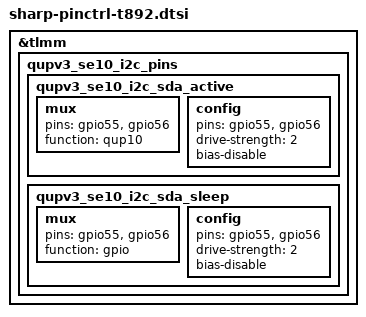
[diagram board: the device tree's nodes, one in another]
/* Copyright (c) 2016-2017, The Linux Foundation. All rights reserved.
 *
 * This program is free software; you can redistribute it and/or modify
 * it under the terms of the GNU General Public License version 2 and
 * only version 2 as published by the Free Software Foundation.
 *
 * This program is distributed in the hope that it will be useful,
 * but WITHOUT ANY WARRANTY; without even the implied warranty of
 * MERCHANTABILITY or FITNESS FOR A PARTICULAR PURPOSE.  See the
 * GNU General Public License for more details.
 */

/*****************************************/
/*  Add SHARP include                    */
/*****************************************/
/* SH_AUDIO_DRIVER -> */ /*A-001*/
#include "sharp-pinctrl-audio-johnny.dtsi"
/* SH_AUDIO_DRIVER <- */ /*A-001*/
#include "sharp-pinctrl-shtps.dtsi"
#include "sharp-pinctrl-dio-sdcc.dtsi"
#include "sharp-pinctrl-sdm845-nfc.dtsi"
#include "sharp-pinctrl-johnny-fpsensor.dtsi"
#include "sharp-pinctrl-shub.dtsi"
#include "sharp-pinctrl-hall.dtsi"

&tlmm {
	/*****************************************/
	/*  I2C                                  */
	/*****************************************/
	/* SE 10 pin mappings */
	qupv3_se10_i2c_pins: qupv3_se10_i2c_pins {
			qupv3_se10_i2c_sda_active: qupv3_se10_i2c_sda_active {
			mux {
				pins = "gpio55", "gpio56";
				function = "qup10";
			};

			config {
				pins = "gpio55", "gpio56";
				drive-strength = <2>;
				bias-disable;
			};
		};

		qupv3_se10_i2c_sda_sleep: qupv3_se10_i2c_sda_sleep {
			mux {
				pins = "gpio55", "gpio56";
				function = "gpio";
			};

			config {
				pins = "gpio55", "gpio56";
				drive-strength = <2>;
				bias-disable;
			};
		};
	};
};

